# nrf9220_sysctrl register map
Vendor: Nordic Semiconductor; Series: nRF92; File version: 1
Registers are 32-bit, read-write, reset 0x0 unless marked. A register's access mark holds for its fields unless they carry their own. Offsets are from the block's base; [hi:lo] are bit positions; lines under a group give offsets from that group; {n}, {i} and the like mark numbered series.

## GLOBAL_EGU130 — Event generator unit
Base 0x5F92D000
{0x0+4i} TASKS_TRIGGER[{i}] (i=0..15) wo — Description collection: Trigger n for triggering the corresponding TRIGGERED[n] event
  [0] TASKS_TRIGGER — Trigger n for triggering the corresponding TRIGGERED[n] event
    1=Trigger task
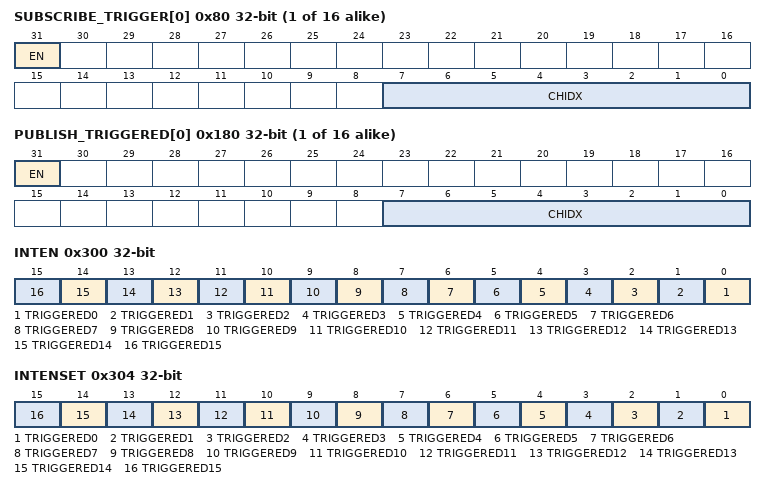
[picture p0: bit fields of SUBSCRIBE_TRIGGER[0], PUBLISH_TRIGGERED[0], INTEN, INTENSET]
{0x80+4i} SUBSCRIBE_TRIGGER[{i}] (i=0..15) — Description collection: Subscribe configuration for task TRIGGER[n]
  [31] EN
    0=Disabled (Disable subscription); 1=Enabled (Enable subscription)
  [7:0] CHIDX — DPPI channel that task TRIGGER[n] will subscribe to
{0x100+4i} EVENTS_TRIGGERED[{i}] (i=0..15) — Description collection: Event number n generated by triggering the corresponding TRIGGER[n] task
  [0] EVENTS_TRIGGERED — Event number n generated by triggering the corresponding TRIGGER[n] task
    0=NotGenerated (Event not generated); 1=Generated (Event generated)
{0x180+4i} PUBLISH_TRIGGERED[{i}] (i=0..15) — Description collection: Publish configuration for event TRIGGERED[n]
  [31] EN
    0=Disabled (Disable publishing); 1=Enabled (Enable publishing)
  [7:0] CHIDX — DPPI channel that event TRIGGERED[n] will publish to
0x300 INTEN — Enable or disable interrupt
  [all] fields
    0=Disabled; 1=Enabled
  [n] TRIGGERED{n} (n=0..15) — Enable or disable interrupt for event TRIGGERED[{n}]
0x304 INTENSET — Enable interrupt
  [all] fields
    on read: 0=Disabled (Read: Disabled); 1=Enabled (Read: Enabled) | on write: 1=Set (Enable)
  [n] TRIGGERED{n} (n=0..15) — Write '1' to enable interrupt for event TRIGGERED[{n}]
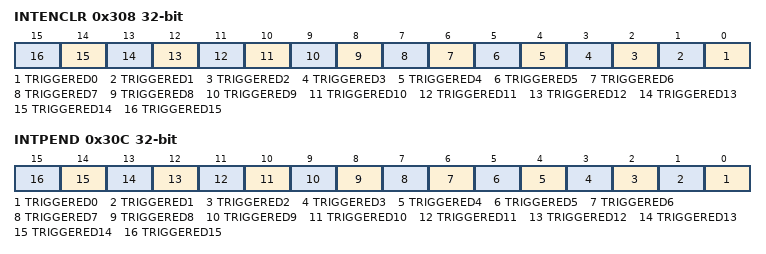
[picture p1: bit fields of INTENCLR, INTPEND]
0x308 INTENCLR — Disable interrupt
  [all] fields
    on read: 0=Disabled (Read: Disabled); 1=Enabled (Read: Enabled) | on write: 1=Clear (Disable)
  [n] TRIGGERED{n} (n=0..15) — Write '1' to disable interrupt for event TRIGGERED[{n}]
0x30C INTPEND ro — Pending interrupts
  [all] fields
    on read: 0=NotPending (Read: Not pending); 1=Pending (Read: Pending)
  [n] TRIGGERED{n} (n=0..15) — Read pending status of interrupt for event TRIGGERED[{n}]

## GLOBAL_GPIOINTERNAL — GPIO Internal
Base 0x5F939E00
0x40 LATCHCLRWAITCNT reset 0x2 — Select the number of wait cycles inserted on the bus when a LATCH register is cleared.
  [1:0] LATCHCLRWAITCNT
0x44 FORCELDETECTLOWCNT reset 0x8 — Select the number of cycles that LDETECT is forced low after clearing a LATCH register.
  [3:0] FORCELDETECTLOWCNT
0x48 RESET — Reset all GPIO registers.
  [0] RESET
    1=RESET (Trigger reset); 0=NA (No effect)
0x4C SENSECONFIGCHANGECNT reset 0x3 — Selects the number of cycles before the SENSE configuration takes effect when it is changed. Setting this register lower than the reset value can lead to unwanted LATCH set when SENSE and INPUT fields (PIN[n].CNF) are changed simultaneously.
  [2:0] SENSECONFIGCHANGECNT — Selects the number of cycles before the SENSE configuration takes effect when it is changed.
0x160 PCGC group — Unspecified
  0x00 TURNOFFAUTOCLOCKSOURCEREQ ro — No functionality
  {0x20+4j} PENALTY[{j}] (j=0..4) ro — Description collection: Penalty level for power/clock pair n
    [7:0] PENALTY — Penalty level
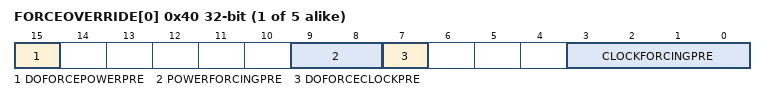
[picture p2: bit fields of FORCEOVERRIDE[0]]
  {0x40+4j} FORCEOVERRIDE[{j}] (j=0..4) ro — Description collection: Force override of power/clock pair n
    [15] DOFORCEPOWERPRE, [9:8] POWERFORCINGPRE, [7] DOFORCECLOCKPRE, [3:0] CLOCKFORCINGPRE

## CLKMON — CLKMON peripheral
Base 0x5F956000
0x100 EVENTS_LFXOERROR — LFXO error detected
  [0] EVENTS_LFXOERROR
    0=NotGenerated (Event not generated); 1=Generated (Event generated)
0x300 INTEN — Enable or disable interrupt
  [0] LFXOERROR — Enable or disable interrupt for event LFXOERROR
    0=Disabled; 1=Enabled
0x304 INTENSET — Enable interrupt
  [0] LFXOERROR — Write '1' to enable interrupt for event LFXOERROR
    on read: 0=Disabled (Read: Disabled); 1=Enabled (Read: Enabled) | on write: 1=Set (Enable)
0x308 INTENCLR — Disable interrupt
  [0] LFXOERROR — Write '1' to disable interrupt for event LFXOERROR
    on read: 0=Disabled (Read: Disabled); 1=Enabled (Read: Enabled) | on write: 1=Clear (Disable)
0x30C INTPEND ro — Pending interrupts
  [0] LFXOERROR — Read pending status of interrupt for event LFXOERROR
    on read: 0=NotPending (Read: Not pending); 1=Pending (Read: Pending)
0x400 STATUS ro — Clock monitor status
  [0] ERROR — LFXO error status
    0=NotDetected (No error detected); 1=Detected (Error detected)
0x404 ENABLE — Enable the clock monitor
  [0] EN — Enable
    0=Disabled (Clock monitor disabled); 1=Enabled (Clock monitor enabled)
